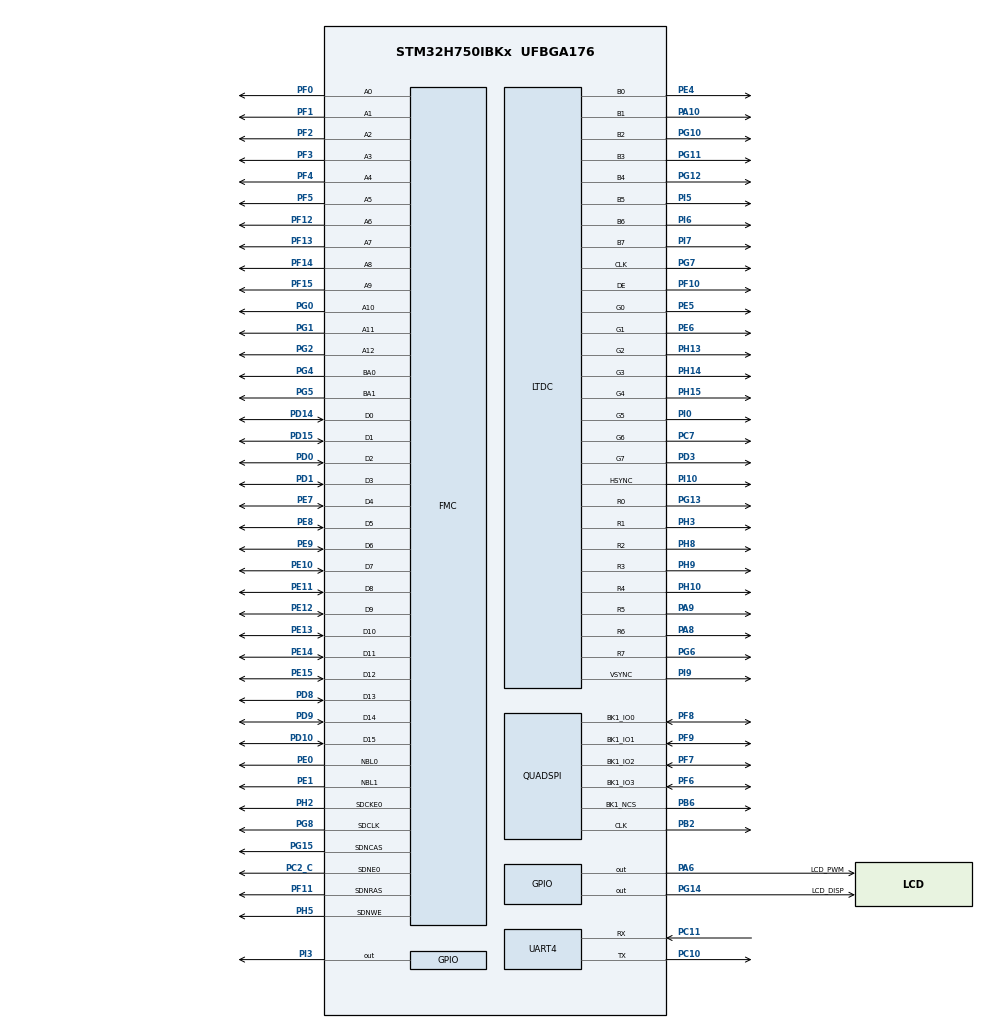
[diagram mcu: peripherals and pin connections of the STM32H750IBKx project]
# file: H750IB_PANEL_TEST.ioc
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CORTEX_M7.CPU_DCache=Disabled
CORTEX_M7.CPU_ICache=Disabled
CORTEX_M7.MPU_Control=__NULL
DMA2D.ColorMode=DMA2D_OUTPUT_RGB888
FMC.CASLatency1=FMC_SDRAM_CAS_LATENCY_3
FMC.ColumnBitsNumber1=FMC_SDRAM_COLUMN_BITS_NUM_9
FMC.ExitSelfRefreshDelay1=9
FMC.LoadToActiveDelay1=2
FMC.RCDDelay1=2
FMC.RPDelay1=2
FMC.RPDelay2=2
FMC.ReadBurst1=FMC_SDRAM_RBURST_ENABLE
FMC.ReadBurst2=FMC_SDRAM_RBURST_ENABLE
FMC.RowCycleDelay1=8
FMC.RowCycleDelay2=8
FMC.SDClockPeriod1=FMC_SDRAM_CLOCK_PERIOD_2
FMC.SDClockPeriod2=FMC_SDRAM_CLOCK_PERIOD_2
FMC.SelfRefreshTime1=5
FMC.WriteRecoveryTime1=5
JPEG.JPEG_RGB_FORMAT=JPEG_RGB888
LTDC.ActiveH=272
LTDC.ActiveW=480
LTDC.Alpha_L0=0xFF
LTDC.Alpha_L1=0xFF
LTDC.BlendingFactor1_L0=LTDC_BLENDING_FACTOR1_PAxCA
LTDC.BlendingFactor1_L1=LTDC_BLENDING_FACTOR1_PAxCA
LTDC.BlendingFactor2_L0=LTDC_BLENDING_FACTOR2_PAxCA
LTDC.BlendingFactor2_L1=LTDC_BLENDING_FACTOR2_PAxCA
LTDC.Blue_L0=0
LTDC.FBStartAdress_L0=0xC0000000
LTDC.FBStartAdress_L1=0xC007F800
LTDC.Green_L0=0
LTDC.HBP=43
LTDC.HFP=8
LTDC.HSync=4
LTDC.ImageHeight_L0=272
LTDC.ImageHeight_L1=272
LTDC.ImageWidth_L0=480
LTDC.ImageWidth_L1=480
LTDC.Layers=1
LTDC.PCPolarity=LTDC_PCPOLARITY_IIPC
LTDC.PixelFormat_L0=LTDC_PIXEL_FORMAT_ARGB8888
LTDC.PixelFormat_L1=LTDC_PIXEL_FORMAT_ARGB8888
LTDC.Red_L0=0
LTDC.VBP=12
LTDC.VFP=8
LTDC.VSync=4
LTDC.WindowX1_L0=480
LTDC.WindowX1_L1=480
LTDC.WindowY1_L0=272
LTDC.WindowY1_L1=272
Mcu.Family=STM32H7
Mcu.Name=STM32H750IBKx
Mcu.Package=UFBGA176
Mdma.MDMA_Channel0.JPEG_INFIFO_TH.0.BlockCount=0
Mdma.MDMA_Channel0.JPEG_INFIFO_TH.0.BlockDataLength=0
Mdma.MDMA_Channel0.JPEG_INFIFO_TH.0.BufferTransferLength=32
Mdma.MDMA_Channel0.JPEG_INFIFO_TH.0.CircularMode=MDMA_LINEAR_LIST
Mdma.MDMA_Channel0.JPEG_INFIFO_TH.0.DataAlignment=MDMA_DATAALIGN_PACKENABLE
Mdma.MDMA_Channel0.JPEG_INFIFO_TH.0.DestBlockAddressOffset=0
Mdma.MDMA_Channel0.JPEG_INFIFO_TH.0.DestBurst=MDMA_DEST_BURST_16BEATS
Mdma.MDMA_Channel0.JPEG_INFIFO_TH.0.DestDataSize=MDMA_DEST_DATASIZE_WORD
Mdma.MDMA_Channel0.JPEG_INFIFO_TH.0.DestinationInc=MDMA_DEST_INC_DISABLE
Mdma.MDMA_Channel0.JPEG_INFIFO_TH.0.DstAddress=0
Mdma.MDMA_Channel0.JPEG_INFIFO_TH.0.Endianness=MDMA_LITTLE_ENDIANNESS_PRESERVE
Mdma.MDMA_Channel0.JPEG_INFIFO_TH.0.Instance=MDMA_Channel0
Mdma.MDMA_Channel0.JPEG_INFIFO_TH.0.MaskAddress=0
Mdma.MDMA_Channel0.JPEG_INFIFO_TH.0.MaskData=0
Mdma.MDMA_Channel0.JPEG_INFIFO_TH.0.Priority=MDMA_PRIORITY_LOW
Mdma.MDMA_Channel0.JPEG_INFIFO_TH.0.Rank=First
Mdma.MDMA_Channel0.JPEG_INFIFO_TH.0.SourceBlockAddressOffset=0
Mdma.MDMA_Channel0.JPEG_INFIFO_TH.0.SourceBurst=MDMA_SOURCE_BURST_32BEATS
Mdma.MDMA_Channel0.JPEG_INFIFO_TH.0.SourceDataSize=MDMA_SRC_DATASIZE_BYTE
Mdma.MDMA_Channel0.JPEG_INFIFO_TH.0.SourceInc=MDMA_SRC_INC_BYTE
Mdma.MDMA_Channel0.JPEG_INFIFO_TH.0.SrcAddress=0
Mdma.MDMA_Channel0.JPEG_INFIFO_TH.0.TransferTriggerMode=MDMA_BUFFER_TRANSFER
Mdma.MDMA_Channel0.Request0=JPEG_INFIFO_TH
Mdma.MDMA_Channel0.RequestsNb=1
Mdma.MDMA_Channel1.JPEG_OUTFIFO_TH.0.BlockCount=0
Mdma.MDMA_Channel1.JPEG_OUTFIFO_TH.0.BlockDataLength=0
Mdma.MDMA_Channel1.JPEG_OUTFIFO_TH.0.BufferTransferLength=32
Mdma.MDMA_Channel1.JPEG_OUTFIFO_TH.0.CircularMode=MDMA_LINEAR_LIST
Mdma.MDMA_Channel1.JPEG_OUTFIFO_TH.0.DataAlignment=MDMA_DATAALIGN_PACKENABLE
Mdma.MDMA_Channel1.JPEG_OUTFIFO_TH.0.DestBlockAddressOffset=0
Mdma.MDMA_Channel1.JPEG_OUTFIFO_TH.0.DestBurst=MDMA_DEST_BURST_32BEATS
Mdma.MDMA_Channel1.JPEG_OUTFIFO_TH.0.DestDataSize=MDMA_DEST_DATASIZE_BYTE
Mdma.MDMA_Channel1.JPEG_OUTFIFO_TH.0.DestinationInc=MDMA_DEST_INC_BYTE
Mdma.MDMA_Channel1.JPEG_OUTFIFO_TH.0.DstAddress=0
Mdma.MDMA_Channel1.JPEG_OUTFIFO_TH.0.Endianness=MDMA_LITTLE_ENDIANNESS_PRESERVE
Mdma.MDMA_Channel1.JPEG_OUTFIFO_TH.0.Instance=MDMA_Channel1
Mdma.MDMA_Channel1.JPEG_OUTFIFO_TH.0.MaskAddress=0
Mdma.MDMA_Channel1.JPEG_OUTFIFO_TH.0.MaskData=0
Mdma.MDMA_Channel1.JPEG_OUTFIFO_TH.0.Priority=MDMA_PRIORITY_LOW
Mdma.MDMA_Channel1.JPEG_OUTFIFO_TH.0.Rank=First
Mdma.MDMA_Channel1.JPEG_OUTFIFO_TH.0.SourceBlockAddressOffset=0
Mdma.MDMA_Channel1.JPEG_OUTFIFO_TH.0.SourceBurst=MDMA_SOURCE_BURST_32BEATS
Mdma.MDMA_Channel1.JPEG_OUTFIFO_TH.0.SourceDataSize=MDMA_SRC_DATASIZE_WORD
Mdma.MDMA_Channel1.JPEG_OUTFIFO_TH.0.SourceInc=MDMA_SRC_INC_DISABLE
Mdma.MDMA_Channel1.JPEG_OUTFIFO_TH.0.SrcAddress=0
Mdma.MDMA_Channel1.JPEG_OUTFIFO_TH.0.TransferTriggerMode=MDMA_BUFFER_TRANSFER
Mdma.MDMA_Channel1.Request0=JPEG_OUTFIFO_TH
Mdma.MDMA_Channel1.RequestsNb=1
Mdma.RequestSet0=MDMA_Channel0
Mdma.RequestSet1=MDMA_Channel1
Mdma.RequestSetsNb=2
NVIC.JPEG_IRQn=true\:0\:0\:false\:false\:true\:true\:true
NVIC.LTDC_IRQn=true\:0\:0\:false\:false\:true\:true\:true
NVIC.MDMA_IRQn=true\:0\:0\:false\:false\:true\:false\:true
NVIC.PriorityGroup=NVIC_PRIORITYGROUP_4
PA10.GPIO_Speed=GPIO_SPEED_FREQ_HIGH
PA10.Mode=RGB888
PA10.Signal=LTDC_B1
PA13\ (JTMS/SWDIO).Mode=Trace_Asynchronous_SW
PA13\ (JTMS/SWDIO).Signal=DEBUG_JTMS-SWDIO
PA14\ (JTCK/SWCLK).Mode=Trace_Asynchronous_SW
PA14\ (JTCK/SWCLK).Signal=DEBUG_JTCK-SWCLK
PA6.GPIO_Label=LCD_PWM
PA6.PinState=GPIO_PIN_SET
PA6.Signal=GPIO_Output
PA8.GPIO_Speed=GPIO_SPEED_FREQ_HIGH
PA8.Mode=RGB888
PA8.Signal=LTDC_R6
PA9.GPIO_Speed=GPIO_SPEED_FREQ_HIGH
PA9.Mode=RGB888
PA9.Signal=LTDC_R5
PB2.GPIO_Speed=GPIO_SPEED_FREQ_VERY_HIGH
PB2.Mode=Single Bank 1
PB2.Signal=QUADSPI_CLK
PB3\ (JTDO/TRACESWO).Mode=Trace_Asynchronous_SW
PB3\ (JTDO/TRACESWO).Signal=DEBUG_JTDO-SWO
PB6.GPIO_Speed=GPIO_SPEED_FREQ_VERY_HIGH
PB6.Mode=Single Bank 1
PB6.Signal=QUADSPI_BK1_NCS
PC10.Mode=Asynchronous
PC10.Signal=UART4_TX
PC11.Mode=Asynchronous
PC11.Signal=UART4_RX
PC2_C.Mode=SdramChipSelect1_1
PC2_C.Signal=FMC_SDNE0
PC7.GPIO_Speed=GPIO_SPEED_FREQ_HIGH
PC7.Mode=RGB888
PC7.Signal=LTDC_G6
PD0.Signal=FMC_D2_DA2
PD1.Signal=FMC_D3_DA3
PD10.Signal=FMC_D15_DA15
PD14.Signal=FMC_D0_DA0
PD15.Signal=FMC_D1_DA1
PD3.GPIO_Speed=GPIO_SPEED_FREQ_HIGH
PD3.Mode=RGB888
PD3.Signal=LTDC_G7
PD8.Signal=FMC_D13_DA13
PD9.Signal=FMC_D14_DA14
PE0.Signal=FMC_NBL0
PE1.Signal=FMC_NBL1
PE10.Signal=FMC_D7_DA7
PE11.Signal=FMC_D8_DA8
PE12.Signal=FMC_D9_DA9
PE13.Signal=FMC_D10_DA10
PE14.Signal=FMC_D11_DA11
PE15.Signal=FMC_D12_DA12
PE4.GPIO_Speed=GPIO_SPEED_FREQ_HIGH
PE4.Mode=RGB888
PE4.Signal=LTDC_B0
PE5.GPIO_Speed=GPIO_SPEED_FREQ_HIGH
PE5.Mode=RGB888
PE5.Signal=LTDC_G0
PE6.GPIO_Speed=GPIO_SPEED_FREQ_HIGH
PE6.Mode=RGB888
PE6.Signal=LTDC_G1
PE7.Signal=FMC_D4_DA4
PE8.Signal=FMC_D5_DA5
PE9.Signal=FMC_D6_DA6
PF0.Signal=FMC_A0
PF1.Signal=FMC_A1
PF10.GPIO_Speed=GPIO_SPEED_FREQ_HIGH
PF10.Mode=RGB888
PF10.Signal=LTDC_DE
PF11.Signal=FMC_SDNRAS
PF12.Signal=FMC_A6
PF13.Signal=FMC_A7
PF14.Signal=FMC_A8
PF15.Signal=FMC_A9
PF2.Signal=FMC_A2
PF3.Signal=FMC_A3
PF4.Signal=FMC_A4
PF5.Signal=FMC_A5
PF6.GPIO_Speed=GPIO_SPEED_FREQ_VERY_HIGH
PF6.Mode=Single Bank 1
PF6.Signal=QUADSPI_BK1_IO3
PF7.GPIO_Speed=GPIO_SPEED_FREQ_VERY_HIGH
PF7.Mode=Single Bank 1
PF7.Signal=QUADSPI_BK1_IO2
PF8.GPIO_Speed=GPIO_SPEED_FREQ_VERY_HIGH
PF8.Mode=Single Bank 1
PF8.Signal=QUADSPI_BK1_IO0
PF9.GPIO_Speed=GPIO_SPEED_FREQ_VERY_HIGH
PF9.Mode=Single Bank 1
PF9.Signal=QUADSPI_BK1_IO1
PG0.Signal=FMC_A10
PG1.Signal=FMC_A11
PG10.GPIO_Speed=GPIO_SPEED_FREQ_HIGH
PG10.Mode=RGB888
PG10.Signal=LTDC_B2
PG11.GPIO_Speed=GPIO_SPEED_FREQ_HIGH
PG11.Mode=RGB888
PG11.Signal=LTDC_B3
PG12.GPIO_Speed=GPIO_SPEED_FREQ_HIGH
PG12.Mode=RGB888
PG12.Signal=LTDC_B4
PG13.GPIO_Speed=GPIO_SPEED_FREQ_HIGH
PG13.Mode=RGB888
PG13.Signal=LTDC_R0
PG14.GPIO_Label=LCD_DISP
PG14.PinState=GPIO_PIN_SET
PG14.Signal=GPIO_Output
PG15.Signal=FMC_SDNCAS
PG2.Signal=FMC_A12
PG4.Signal=FMC_A14_BA0
PG5.Signal=FMC_A15_BA1
PG6.GPIO_Speed=GPIO_SPEED_FREQ_HIGH
PG6.Mode=RGB888
PG6.Signal=LTDC_R7
PG7.GPIO_Speed=GPIO_SPEED_FREQ_HIGH
PG7.Mode=RGB888
PG7.Signal=LTDC_CLK
PG8.Signal=FMC_SDCLK
PH10.GPIO_Speed=GPIO_SPEED_FREQ_HIGH
PH10.Mode=RGB888
PH10.Signal=LTDC_R4
PH13.GPIO_Speed=GPIO_SPEED_FREQ_HIGH
PH13.Mode=RGB888
PH13.Signal=LTDC_G2
PH14.GPIO_Speed=GPIO_SPEED_FREQ_HIGH
PH14.Mode=RGB888
PH14.Signal=LTDC_G3
PH15.GPIO_Speed=GPIO_SPEED_FREQ_HIGH
PH15.Mode=RGB888
PH15.Signal=LTDC_G4
PH2.Mode=SdramChipSelect1_1
PH2.Signal=FMC_SDCKE0
PH3.GPIO_Speed=GPIO_SPEED_FREQ_HIGH
PH3.Mode=RGB888
PH3.Signal=LTDC_R1
PH5.Signal=FMC_SDNWE
PH8.GPIO_Speed=GPIO_SPEED_FREQ_HIGH
PH8.Mode=RGB888
PH8.Signal=LTDC_R2
PH9.GPIO_Speed=GPIO_SPEED_FREQ_HIGH
PH9.Mode=RGB888
PH9.Signal=LTDC_R3
PI0.GPIO_Speed=GPIO_SPEED_FREQ_HIGH
PI0.Mode=RGB888
PI0.Signal=LTDC_G5
PI10.GPIO_Speed=GPIO_SPEED_FREQ_HIGH
PI10.Mode=RGB888
PI10.Signal=LTDC_HSYNC
PI3.Signal=GPIO_Output
PI5.GPIO_Speed=GPIO_SPEED_FREQ_HIGH
PI5.Mode=RGB888
PI5.Signal=LTDC_B5
PI6.GPIO_Speed=GPIO_SPEED_FREQ_HIGH
PI6.Mode=RGB888
PI6.Signal=LTDC_B6
PI7.GPIO_Speed=GPIO_SPEED_FREQ_HIGH
PI7.Mode=RGB888
PI7.Signal=LTDC_B7
PI9.GPIO_Speed=GPIO_SPEED_FREQ_HIGH
PI9.Mode=RGB888
PI9.Signal=LTDC_VSYNC
ProjectManager.HeapSize=0x200
ProjectManager.StackSize=0x80000
ProjectManager.TargetToolchain=MDK-ARM V5.32
QUADSPI.ChipSelectHighTime=QSPI_CS_HIGH_TIME_4_CYCLE
QUADSPI.ClockPrescaler=1
QUADSPI.FlashSize=25
QUADSPI.SampleShifting=QSPI_SAMPLE_SHIFTING_HALFCYCLE
RCC.ADCFreq_Value=129000000
RCC.APB1Freq_Value=120000000
RCC.APB2Freq_Value=120000000
RCC.APB3Freq_Value=120000000
RCC.APB4Freq_Value=120000000
RCC.CortexFreq_Value=240000000
RCC.DIVM3=30
RCC.DIVN1=240
RCC.DIVN3=127
RCC.DIVR3=30
RCC.HCLKFreq_Value=120000000
RCC.HPRE=RCC_HCLK_DIV2
RCC.SYSCLKFreq_VALUE=240000000
RCC.SYSCLKSource=RCC_SYSCLKSOURCE_PLLCLK
RCC.USART234578CLockSelection=RCC_USART234578CLKSOURCE_HSI
RCC.USBFreq_Value=240000000
SH.FMC_A0.0=FMC_A0,13b-sda1
SH.FMC_A1.0=FMC_A1,13b-sda1
SH.FMC_A10.0=FMC_A10,13b-sda1
SH.FMC_A11.0=FMC_A11,13b-sda1
SH.FMC_A12.0=FMC_A12,13b-sda1
SH.FMC_A14_BA0.0=FMC_BA0,FourSdramBanks1
SH.FMC_A15_BA1.0=FMC_BA1,FourSdramBanks1
SH.FMC_A2.0=FMC_A2,13b-sda1
SH.FMC_A3.0=FMC_A3,13b-sda1
SH.FMC_A4.0=FMC_A4,13b-sda1
SH.FMC_A5.0=FMC_A5,13b-sda1
SH.FMC_A6.0=FMC_A6,13b-sda1
SH.FMC_A7.0=FMC_A7,13b-sda1
SH.FMC_A8.0=FMC_A8,13b-sda1
SH.FMC_A9.0=FMC_A9,13b-sda1
SH.FMC_D0_DA0.0=FMC_D0,sd-16b-d1
SH.FMC_D10_DA10.0=FMC_D10,sd-16b-d1
SH.FMC_D11_DA11.0=FMC_D11,sd-16b-d1
SH.FMC_D12_DA12.0=FMC_D12,sd-16b-d1
SH.FMC_D13_DA13.0=FMC_D13,sd-16b-d1
SH.FMC_D14_DA14.0=FMC_D14,sd-16b-d1
SH.FMC_D15_DA15.0=FMC_D15,sd-16b-d1
SH.FMC_D1_DA1.0=FMC_D1,sd-16b-d1
SH.FMC_D2_DA2.0=FMC_D2,sd-16b-d1
SH.FMC_D3_DA3.0=FMC_D3,sd-16b-d1
SH.FMC_D4_DA4.0=FMC_D4,sd-16b-d1
SH.FMC_D5_DA5.0=FMC_D5,sd-16b-d1
SH.FMC_D6_DA6.0=FMC_D6,sd-16b-d1
SH.FMC_D7_DA7.0=FMC_D7,sd-16b-d1
SH.FMC_D8_DA8.0=FMC_D8,sd-16b-d1
SH.FMC_D9_DA9.0=FMC_D9,sd-16b-d1
SH.FMC_NBL0.0=FMC_NBL0,Sd2ByteEnable1
SH.FMC_NBL1.0=FMC_NBL1,Sd2ByteEnable1
SH.FMC_SDCLK.0=FMC_SDCLK,13b-sda1
SH.FMC_SDNCAS.0=FMC_SDNCAS,13b-sda1
SH.FMC_SDNRAS.0=FMC_SDNRAS,13b-sda1
SH.FMC_SDNWE.0=FMC_SDNWE,13b-sda1
VP_DMA2D_VS_DMA2D.Mode=DMA2D_Activate
VP_JPEG_VS_JPEG.Mode=JPEG_Activate
board=custom

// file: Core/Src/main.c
/* USER CODE BEGIN Header */
/**
  ******************************************************************************
  * @file           : main.c
  * @brief          : Main program body
  ******************************************************************************
  * @attention
  *
  * Copyright (c) 2022 STMicroelectronics.
  * All rights reserved.
  *
  * This software is licensed under terms that can be found in the LICENSE file
  * in the root directory of this software component.
  * If no LICENSE file comes with this software, it is provided AS-IS.
  *
  ******************************************************************************
  */
/* USER CODE END Header */
#include "main.h"
#include "dma2d.h"
#include "jpeg.h"
#include "ltdc.h"
#include "mdma.h"
#include "quadspi.h"
#include "usart.h"
#include "gpio.h"
#include "fmc.h"

/* USER CODE BEGIN Includes */
#include "bsp_qspi_w25q256.h"
#include "w9825g6jb.h"
#include <stdio.h>
/* USER CODE END Includes */

/* USER CODE BEGIN PV */
int fputc(int c, FILE *stream)    //??fputc??
{

    HAL_UART_Transmit(&huart4, (unsigned char *)&c, 1, 1000);
    return 1;
}
/* USER CODE END PV */

void SystemClock_Config(void);
/* USER CODE BEGIN PFP */
extern unsigned char image_320_240_jpg[23127];
extern __IO uint32_t Jpeg_HWDecodingEnd;
/* USER CODE END PFP */

int main(void)
{
  /* USER CODE BEGIN 1 */
	JPEG_ConfTypeDef JPEG_Info={0};

	int count;

	W9825G6JB_Context_t SDRAM_REG={0};

	SDRAM_REG.BurstLength=W9825G6JB_BURST_LENGTH_1;
	SDRAM_REG.BurstType=W9825G6JB_BURST_TYPE_SEQUENTIAL;
	SDRAM_REG.CASLatency=W9825G6JB_CAS_LATENCY_3;
	SDRAM_REG.OperationMode=W9825G6JB_OPERATING_MODE_STANDARD;
	SDRAM_REG.RefreshMode=W9825G6JB_AUTOREFRESH_MODE_CMD;
	SDRAM_REG.RefreshRate=REFRESH_COUNT;
	SDRAM_REG.TargetBank=FMC_SDRAM_CMD_TARGET_BANK1;
	SDRAM_REG.WriteBurstMode=W9825G6JB_WRITEBURST_MODE_SINGLE;
  /* USER CODE END 1 */

  /* MCU Configuration--------------------------------------------------------*/

  /* Reset of all peripherals, Initializes the Flash interface and the Systick. */
  HAL_Init();

  /* Configure the system clock */
  SystemClock_Config();

  /* Initialize all configured peripherals */
  MX_GPIO_Init();
  MX_FMC_Init();
  MX_QUADSPI_Init();
  MX_LTDC_Init();
  MX_DMA2D_Init();
  MX_MDMA_Init();
  MX_JPEG_Init();
  MX_UART4_Init();
  /* USER CODE BEGIN 2 */
	if(BSP_QSPI_W25Q256_Init() != QSPI_OK)
	{
		//printf("BSP_QSPI_W25Q256_Init fail\r\n");
		HAL_GPIO_WritePin(GPIOG, GPIO_PIN_14, GPIO_PIN_RESET);
		HAL_GPIO_WritePin(GPIOA, GPIO_PIN_6, GPIO_PIN_RESET);
	}
	if(BSP_QSPI_W25Q256_EnableMemoryMappedMode() != QSPI_OK)
	{
		//printf("BSP_QSPI_W25Q256_EnableMemoryMappedMode fail\r\n");
		HAL_GPIO_WritePin(GPIOG, GPIO_PIN_14, GPIO_PIN_RESET);
		HAL_GPIO_WritePin(GPIOA, GPIO_PIN_6, GPIO_PIN_RESET);
	}
	if(W9825G6JB_Init(&hsdram1,&SDRAM_REG))
	{
		HAL_GPIO_WritePin(GPIOG, GPIO_PIN_14, GPIO_PIN_RESET);
		HAL_GPIO_WritePin(GPIOA, GPIO_PIN_6, GPIO_PIN_RESET);
	}

	printf("Hello\r\n");

	//HAL_LTDC_SetAlpha(&hltdc,0x80,Layer1);

	DMA2D_Convert_MemCopy(LTDC_PIXEL_FORMAT_RGB888,0x90000000,Layer0_Start_Address,480,270,0,0,LTDC_PIXEL_FORMAT_ARGB8888);

	//Fill_Rec_DMA2D(0,0,480,272,0x00FF0000,Layer0);

//	LTDC_Fill_Rec(LTDC_PIXEL_FORMAT_ARGB8888,0,0,480,272,0xFFFFFFFF,Layer1);

	count = JPEG_Length_Check(Bird);

	LTDC_Jpeg((uint32_t*)Bird,(uint32_t*)JPEG_PFC_BUFFER,count,0,0,0xFF,LTDC_PIXEL_FORMAT_ARGB8888,Layer1);

	if(LTDC->SRCR & 0x01){
		LTDC_Fill_Rec(LTDC_PIXEL_FORMAT_ARGB8888,400,200,70,60,0xFFFF0000,Layer1);
	}
		else if (LTDC->SRCR & 0x02){
			LTDC_Fill_Rec(LTDC_PIXEL_FORMAT_ARGB8888,400,200,70,60,0xFF00FF00,Layer1);
		}
			else LTDC_Fill_Rec(LTDC_PIXEL_FORMAT_ARGB8888,400,200,70,60,0xFFFFFFFF,Layer1);

	//DMA2D_Convert_MemCopy(LTDC_PIXEL_FORMAT_RGB888,0x90000000,Layer1_Start_Address,480,270,0,0,LTDC_PIXEL_FORMAT_ARGB8888);

//		LTDC_Jpeg((uint32_t*)0x90060000,(uint32_t*)0xC0100000,(uint32_t*)Layer1_Start_Address,0x15F4,0,0,LTDC_PIXEL_FORMAT_ARGB8888,1);

//	JPEG_Decode_DMA(&hjpeg, 0x90060000, 0x15F4, 0xC0100000);
//
//	while(Jpeg_HWDecodingEnd!=1){
//
//	}
//
//	HAL_JPEG_GetInfo(&hjpeg, &JPEG_Info);
//
//	DMA2D_Copy_YCbCr_To_RGB((uint32_t*)0xC0100000,(uint32_t*)0xC007F800,0,0,JPEG_Info.ImageWidth,JPEG_Info.ImageHeight,LTDC_PIXEL_FORMAT_ARGB8888,JPEG_Info.ChromaSubsampling);
//
//	while(Jpeg_HWDecodingEnd!=1){
//
//	}
  /* USER CODE END 2 */

  /* Infinite loop */
  while (1)
  {

  }
}

void SystemClock_Config(void)
{
  RCC_OscInitTypeDef RCC_OscInitStruct = {0};
  RCC_ClkInitTypeDef RCC_ClkInitStruct = {0};

  /** Supply configuration update enable
  */
  HAL_PWREx_ConfigSupply(PWR_LDO_SUPPLY);
  /** Configure the main internal regulator output voltage
  */
  __HAL_PWR_VOLTAGESCALING_CONFIG(PWR_REGULATOR_VOLTAGE_SCALE2);

  while(!__HAL_PWR_GET_FLAG(PWR_FLAG_VOSRDY)) {}
  /** Macro to configure the PLL clock source
  */
  __HAL_RCC_PLL_PLLSOURCE_CONFIG(RCC_PLLSOURCE_HSI);
  /** Initializes the RCC Oscillators according to the specified parameters
  * in the RCC_OscInitTypeDef structure.
  */
  RCC_OscInitStruct.OscillatorType = RCC_OSCILLATORTYPE_HSI;
  RCC_OscInitStruct.HSIState = RCC_HSI_DIV1;
  RCC_OscInitStruct.HSICalibrationValue = RCC_HSICALIBRATION_DEFAULT;
  RCC_OscInitStruct.PLL.PLLState = RCC_PLL_ON;
  RCC_OscInitStruct.PLL.PLLSource = RCC_PLLSOURCE_HSI;
  RCC_OscInitStruct.PLL.PLLM = 32;
  RCC_OscInitStruct.PLL.PLLN = 240;
  RCC_OscInitStruct.PLL.PLLP = 2;
  RCC_OscInitStruct.PLL.PLLQ = 2;
  RCC_OscInitStruct.PLL.PLLR = 2;
  RCC_OscInitStruct.PLL.PLLRGE = RCC_PLL1VCIRANGE_1;
  RCC_OscInitStruct.PLL.PLLVCOSEL = RCC_PLL1VCOWIDE;
  RCC_OscInitStruct.PLL.PLLFRACN = 0;
  if (HAL_RCC_OscConfig(&RCC_OscInitStruct) != HAL_OK)
  {
    Error_Handler();
  }
  /** Initializes the CPU, AHB and APB buses clocks
  */
  RCC_ClkInitStruct.ClockType = RCC_CLOCKTYPE_HCLK|RCC_CLOCKTYPE_SYSCLK
                              |RCC_CLOCKTYPE_PCLK1|RCC_CLOCKTYPE_PCLK2
                              |RCC_CLOCKTYPE_D3PCLK1|RCC_CLOCKTYPE_D1PCLK1;
  RCC_ClkInitStruct.SYSCLKSource = RCC_SYSCLKSOURCE_PLLCLK;
  RCC_ClkInitStruct.SYSCLKDivider = RCC_SYSCLK_DIV1;
  RCC_ClkInitStruct.AHBCLKDivider = RCC_HCLK_DIV2;
  RCC_ClkInitStruct.APB3CLKDivider = RCC_APB3_DIV1;
  RCC_ClkInitStruct.APB1CLKDivider = RCC_APB1_DIV1;
  RCC_ClkInitStruct.APB2CLKDivider = RCC_APB2_DIV1;
  RCC_ClkInitStruct.APB4CLKDivider = RCC_APB4_DIV1;

  if (HAL_RCC_ClockConfig(&RCC_ClkInitStruct, FLASH_LATENCY_2) != HAL_OK)
  {
    Error_Handler();
  }
}

void Error_Handler(void)
{
  __disable_irq();
  while (1)
  {
  }
}
